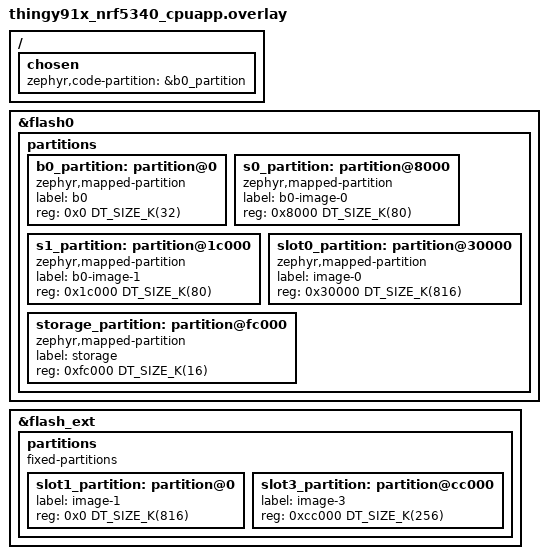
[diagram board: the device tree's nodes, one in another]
/*
 * Copyright (c) 2026 Nordic Semiconductor ASA
 *
 * SPDX-License-Identifier: LicenseRef-Nordic-5-Clause
 */

/* Define partition layout for b0 bootloader.
 * This overlay replaces nrf/samples/bootloader/app.overlay (sysbuild DTC
 * overlays replace, not append), so both the partition definitions and the
 * chosen node from app.overlay must be present here.
 */

/delete-node/ &boot_partition;
/delete-node/ &slot0_partition;
/delete-node/ &slot1_partition;
/delete-node/ &storage_partition;

&flash0 {
	partitions {
		ranges;
		#address-cells = <1>;
		#size-cells = <1>;

		b0_partition: partition@0 {
			compatible = "zephyr,mapped-partition";
			label = "b0";
			reg = <0x0 DT_SIZE_K(32)>;
		};

		s0_partition: partition@8000 {
			compatible = "zephyr,mapped-partition";
			label = "b0-image-0";
			reg = <0x8000 DT_SIZE_K(80)>;
		};

		s1_partition: partition@1c000 {
			compatible = "zephyr,mapped-partition";
			label = "b0-image-1";
			reg = <0x1c000 DT_SIZE_K(80)>;
		};

		slot0_partition: partition@30000 {
			compatible = "zephyr,mapped-partition";
			label = "image-0";
			reg = <0x30000 DT_SIZE_K(816)>;
		};

		storage_partition: partition@fc000 {
			compatible = "zephyr,mapped-partition";
			label = "storage";
			reg = <0xfc000 DT_SIZE_K(16)>;
		};
	};
};

/* MCUboot secondary slot in external flash */
&flash_ext {
	partitions {
		compatible = "fixed-partitions";
		#address-cells = <1>;
		#size-cells = <1>;

		slot1_partition: partition@0 {
			label = "image-1";
			reg = <0x0 DT_SIZE_K(816)>;
		};

		slot3_partition: partition@cc000 {
			label = "image-3";
			reg = <0xcc000 DT_SIZE_K(256)>;
		};
	};
};

/ {
	chosen {
		zephyr,code-partition = &b0_partition;
	};
};
